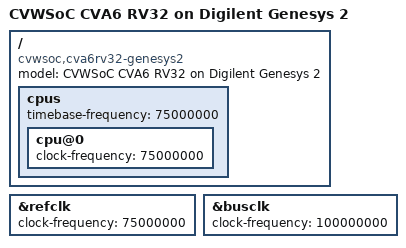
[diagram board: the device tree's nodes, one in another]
/dts-v1/;

 /include/ "cvwsoc-cpu-cva6rv32.dtsi"
 /include/ "cvwsoc.dtsi"
 /include/ "cvwsoc-board-genesys2.dtsi"

/ {
  model = "CVWSoC CVA6 RV32 on Digilent Genesys 2";
  compatible = "cvwsoc,cva6rv32-genesys2", "cvwsoc,cvwsoc";

  cpus {
    timebase-frequency = <75000000>;
    cpu@0 {
      clock-frequency = <75000000>;
    };
  };


};

&refclk { clock-frequency = <75000000>; };
&busclk { clock-frequency = <100000000>; };
